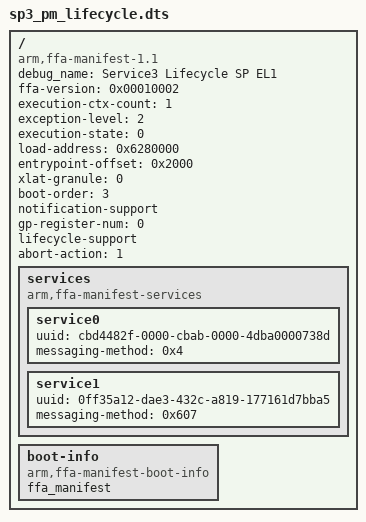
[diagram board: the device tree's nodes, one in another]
/*
 * Copyright 2025 The Hafnium Authors.
 *
 * Use of this source code is governed by a BSD-style
 * license that can be found in the LICENSE file or at
 * https://opensource.org/licenses/BSD-3-Clause.
 */

/dts-v1/;

/ {
	compatible = "arm,ffa-manifest-1.1";
	debug_name = "Service3 Lifecycle SP EL1";

	/* Properties */
	ffa-version = <0x00010002>; /* 31:16 - Major, 15:0 - Minor */
	execution-ctx-count = <1>;
	exception-level = <2>; /* S-EL1 */
	execution-state = <0>; /* AARCH64 */
	load-address = <0x6280000>;
	entrypoint-offset = <0x2000>;
	xlat-granule = <0>; /* 4KiB */
	boot-order = <3>;
	notification-support; /* Receipt of notifications. */
	gp-register-num = <0>;
	lifecycle-support;
	abort-action = <1>; /* Destroy */

	services {
		compatible = "arm,ffa-manifest-services";

		service0 {
			uuid = "cbd4482f-0000-cbab-0000-4dba0000738d";
			messaging-method = <0x4>; /* Supports indirect requests only. */
		};

		service1 {
			uuid = "0ff35a12-dae3-432c-a819-177161d7bba5";
			messaging-method = <0x607>; /* Supports direct (both APIs) and indirect requests. */

		};
	};

	/* Boot Info */
	boot-info {
		compatible = "arm,ffa-manifest-boot-info";
		ffa_manifest;
	};
};
